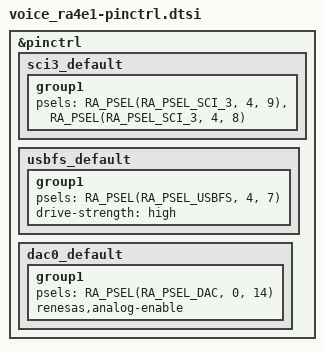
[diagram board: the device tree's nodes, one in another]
/*
 * Copyright (c) 2025 Renesas Electronics Corporation
 * SPDX-License-Identifier: Apache-2.0
 */

&pinctrl {
	sci3_default: sci3_default {
		group1 {
			/* tx rx */
			psels = <RA_PSEL(RA_PSEL_SCI_3, 4, 9)>,
				<RA_PSEL(RA_PSEL_SCI_3, 4, 8)>;
		};
	};

	usbfs_default: usbfs_default {
		group1 {
			/* USB_VBUS */
			psels = <RA_PSEL(RA_PSEL_USBFS, 4, 7)>;
			drive-strength = "high";
		};
	};

	dac0_default: dac0_default {
		group1 {
			/* output */
			psels = <RA_PSEL(RA_PSEL_DAC, 0, 14)>;
			renesas,analog-enable;
		};
	};
};
